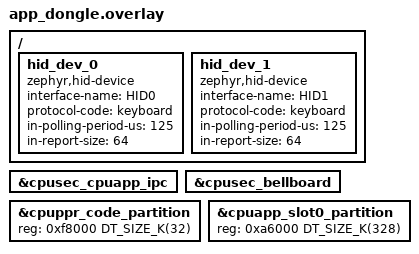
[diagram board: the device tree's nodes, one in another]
/*
 * Copyright (c) 2024 Nordic Semiconductor ASA
 *
 * SPDX-License-Identifier: LicenseRef-Nordic-5-Clause
 */

/ {
	/* Configure DTS nodes used for USB next HID support. */
	hid_dev_0: hid_dev_0 {
		compatible = "zephyr,hid-device";
		interface-name = "HID0";
		protocol-code = "keyboard";
		in-polling-period-us = <125>;
		in-report-size = <64>;
	};
	hid_dev_1: hid_dev_1 {
		compatible = "zephyr,hid-device";
		interface-name = "HID1";
		protocol-code = "keyboard";
		in-polling-period-us = <125>;
		in-report-size = <64>;
	};
};

&cpusec_cpuapp_ipc {
	status = "okay";
};

&cpusec_bellboard {
	status = "okay";
};

/* Shrink ppr partition as ppr core is not used and extend app core code partition. */
&cpuppr_code_partition {
	reg = < 0xf8000 DT_SIZE_K(32) >;
};

&cpuapp_slot0_partition {
	reg = < 0xa6000 DT_SIZE_K(328) >;
};
